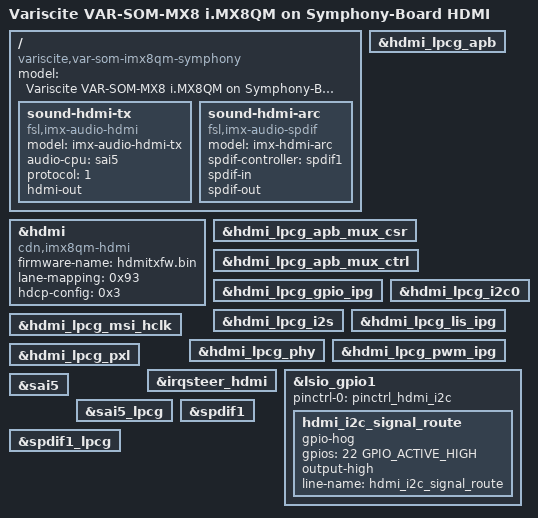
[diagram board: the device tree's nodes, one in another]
// SPDX-License-Identifier: (GPL-2.0+ OR MIT)
/*       
 * Copyright (C) 2026 Variscite Ltd. - https://www.variscite.com/
 *
 */

#include "imx8qm-var-som-symphony.dts"

/ {
	model = "Variscite VAR-SOM-MX8 i.MX8QM on Symphony-Board HDMI";
	compatible = "variscite,var-som-imx8qm-symphony",
		     "variscite,var-som-imx8qm", "fsl,imx8qm";

	sound-hdmi-tx {
		compatible = "fsl,imx-audio-hdmi";
		model = "imx-audio-hdmi-tx";
		audio-cpu = <&sai5>;
		protocol = <1>;
		hdmi-out;
	};

	sound-hdmi-arc {
		compatible = "fsl,imx-audio-spdif";
		model = "imx-hdmi-arc";
		spdif-controller = <&spdif1>;
		spdif-in;
		spdif-out;
	};
};

&hdmi {
	compatible = "cdn,imx8qm-hdmi";
	firmware-name = "hdmitxfw.bin";
	lane-mapping = <0x93>;
	hdcp-config = <0x3>;
	status = "okay";
};

&hdmi_lpcg_apb {
	status = "okay";
};

&hdmi_lpcg_apb_mux_csr {
	status = "okay";
};

&hdmi_lpcg_apb_mux_ctrl {
	status = "okay";
};

&hdmi_lpcg_gpio_ipg {
	status = "okay";
};

&hdmi_lpcg_i2c0 {
	status = "okay";
};

&hdmi_lpcg_i2s {
	status = "okay";
};

&hdmi_lpcg_lis_ipg {
	status = "okay";
};

&hdmi_lpcg_msi_hclk {
	status = "okay";
};

&hdmi_lpcg_phy {
	status = "okay";
};

&hdmi_lpcg_pwm_ipg {
	status = "okay";
};

&hdmi_lpcg_pxl {
	status = "okay";
};

&irqsteer_hdmi {
	status = "okay";
};

&lsio_gpio1 {
	pinctrl-names = "default";
	pinctrl-0 = <&pinctrl_hdmi_i2c>;

	hdmi_i2c_signal_route {
		gpio-hog;
		gpios = <22 GPIO_ACTIVE_HIGH>;
		output-high;
		line-name = "hdmi_i2c_signal_route";
	};
};

&sai5 {
	status = "okay";
};

&sai5_lpcg {
	status = "okay";
};

&spdif1 {
	status = "okay";
};

&spdif1_lpcg {
	status = "okay";
};
